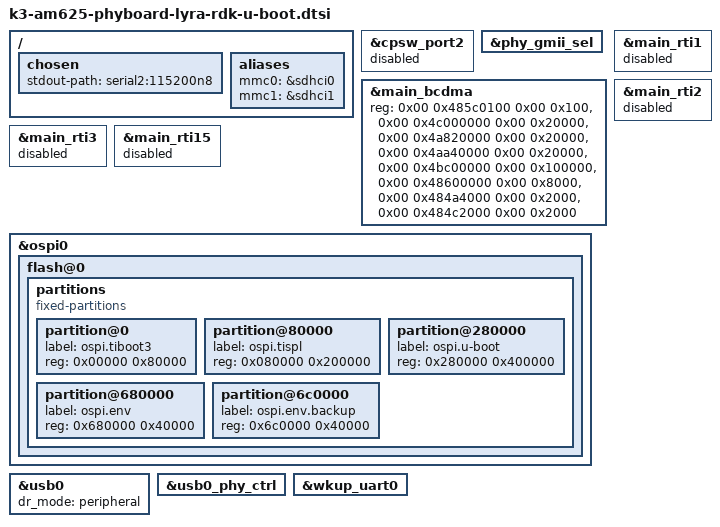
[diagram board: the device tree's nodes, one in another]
// SPDX-License-Identifier: GPL-2.0
/*
 * phyCORE-AM62x dts file for SPLs
 * Copyright (C) 2022 - 2023 Phytec Messtechnik GmbH
 * Author: Wadim Egorov <w.egorov@phytec.de>
 *
 * Product homepage:
 * https://www.phytec.com/product/phyboard-am62x
 */

#include "k3-am625-phycore-som-binman.dtsi"

/ {
	chosen {
		stdout-path = "serial2:115200n8";
	};

	aliases {
		mmc0 = &sdhci0;
		mmc1 = &sdhci1;
	};
};

&cpsw_port2 {
	status = "disabled";
};

&phy_gmii_sel {
	bootph-all;
};

&main_bcdma {
	bootph-all;
	reg = <0x00 0x485c0100 0x00 0x100>,
	      <0x00 0x4c000000 0x00 0x20000>,
	      <0x00 0x4a820000 0x00 0x20000>,
	      <0x00 0x4aa40000 0x00 0x20000>,
	      <0x00 0x4bc00000 0x00 0x100000>,
	      <0x00 0x48600000 0x00 0x8000>,
	      <0x00 0x484a4000 0x00 0x2000>,
	      <0x00 0x484c2000 0x00 0x2000>;
	reg-names = "gcfg", "bchanrt", "rchanrt", "tchanrt",
		    "ringrt" , "cfg", "tchan", "rchan";
};

&main_rti1 {
	status = "disabled";
};

&main_rti2 {
	status = "disabled";
};

&main_rti3 {
	status = "disabled";
};

&main_rti15 {
	status = "disabled";
};

&ospi0 {
	flash@0 {
		partitions {
			compatible = "fixed-partitions";
			#address-cells = <1>;
			#size-cells = <1>;

			partition@0 {
				label = "ospi.tiboot3";
				reg = <0x00000 0x80000>;
			};
			partition@80000 {
				label = "ospi.tispl";
				reg = <0x080000 0x200000>;
			};
			partition@280000 {
				label = "ospi.u-boot";
				reg = <0x280000 0x400000>;
			};
			partition@680000 {
				label = "ospi.env";
				reg = <0x680000 0x40000>;
			};
			partition@6c0000 {
				label = "ospi.env.backup";
				reg = <0x6c0000 0x40000>;
			};
		};
	};
};

&usb0 {
	dr_mode = "peripheral";
};

&usb0_phy_ctrl {
	bootph-all;
};

&wkup_uart0 {
	bootph-all;
};
